# CH32X035 register map
Vendor: WCH Ltd.; File version: 1.2
Registers are 32-bit, read-write, reset 0x0 unless marked. A register's access mark holds for its fields unless they carry their own. Offsets are from the block's base; [hi:lo] are bit positions.

## I2C1 — Inter integrated circuit
Base 0x40005400
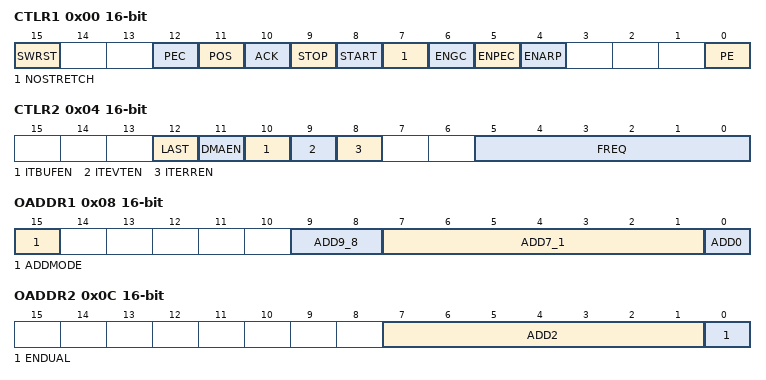
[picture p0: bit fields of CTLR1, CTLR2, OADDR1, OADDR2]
0x00 CTLR1 16-bit — Control register 1
  [15] SWRST — Software reset
  [12] PEC — Packet error checking
  [11] POS — Acknowledge/PEC Position (for data reception)
  [10] ACK — Acknowledge enable
  [9] STOP — Stop generation
  [8] START — Start generation
  [7] NOSTRETCH — Clock stretching disable (Slave mode)
  [6] ENGC — General call enable
  [5] ENPEC — PEC enable
  [4] ENARP — ARP enable
  [0] PE — Peripheral enable
0x04 CTLR2 16-bit — Control register 2
  [12] LAST — DMA last transfer
  [11] DMAEN — DMA requests enable
  [10] ITBUFEN — Buffer interrupt enable
  [9] ITEVTEN — Event interrupt enable
  [8] ITERREN — Error interrupt enable
  [5:0] FREQ — Peripheral clock frequency
0x08 OADDR1 16-bit — Own address register 1
  [15] ADDMODE — Addressing mode (slave mode)
  [9:8] ADD9_8 — Interface address
  [7:1] ADD7_1 — Interface address
  [0] ADD0 — Interface address
0x0C OADDR2 16-bit — Own address register 2
  [7:1] ADD2 — Interface address
  [0] ENDUAL — Dual addressing mode enable
0x10 DATAR 16-bit — Data register
  [7:0] DATAR — 8-bit data register
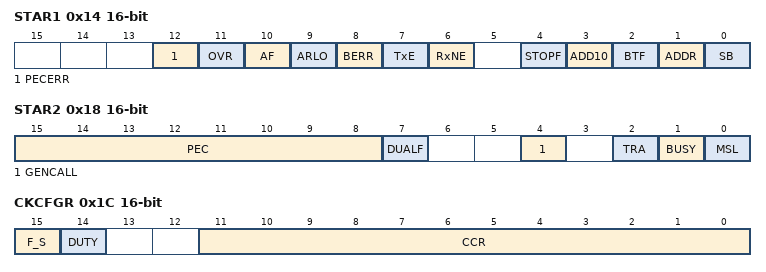
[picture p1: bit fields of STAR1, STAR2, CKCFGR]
0x14 STAR1 16-bit access per field — Status register 1
  [12] PECERR read/clear — PEC Error in reception
  [11] OVR read/clear — Overrun/Underrun
  [10] AF read/clear — Acknowledge failure
  [9] ARLO read/clear — Arbitration lost (master mode)
  [8] BERR read/clear — Bus error
  [7] TxE ro — Data register empty (transmitters)
  [6] RxNE ro — Data register not empty (receivers)
  [4] STOPF ro — Stop detection (slave mode)
  [3] ADD10 ro — 10-bit header sent (Master mode)
  [2] BTF ro — Byte transfer finished
  [1] ADDR read/clear — Address sent (master mode)/matched (slave mode)
  [0] SB ro — Start bit (Master mode)
0x18 STAR2 16-bit ro — Status register 2
  [15:8] PEC
  [7] DUALF — Dual flag (Slave mode)
  [4] GENCALL — General call address (Slave mode)
  [2] TRA — Transmitter/receiver
  [1] BUSY — Bus busy
  [0] MSL — Master/slave
0x1C CKCFGR 16-bit — Clock control register
  [15] F_S — I2C master mode selection
  [14] DUTY — Fast mode duty cycle
  [11:0] CCR — Clock control register in Fast/Standard mode (Master mode)

## SPI1 — Serial peripheral interface
Base 0x40013000
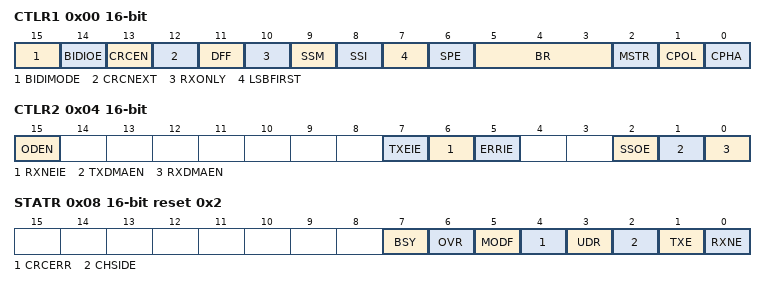
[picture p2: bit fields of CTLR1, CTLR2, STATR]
0x00 CTLR1 16-bit — control register 1
  [15] BIDIMODE — Bidirectional data mode enable
  [14] BIDIOE — Output enable in bidirectional mode
  [13] CRCEN — Hardware CRC calculation enable
  [12] CRCNEXT — CRC transfer next
  [11] DFF — Data frame format
  [10] RXONLY — Receive only
  [9] SSM — Software slave management
  [8] SSI — Internal slave select
  [7] LSBFIRST — Frame format
  [6] SPE — SPI enable
  [5:3] BR — Baud rate control
  [2] MSTR — Master selection
  [1] CPOL — Clock polarity
  [0] CPHA — Clock phase
0x04 CTLR2 16-bit — control register 2
  [15] ODEN — open drain output of SPI pin is enable
  [7] TXEIE — Tx buffer empty interrupt enable
  [6] RXNEIE — RX buffer not empty interrupt enable
  [5] ERRIE — Error interrupt enable
  [2] SSOE — SS output enable
  [1] TXDMAEN — Tx buffer DMA enable
  [0] RXDMAEN — Rx buffer DMA enable
0x08 STATR 16-bit access per field reset 0x2 — status register
  [7] BSY ro — Busy flag
  [6] OVR rw — Overrun flag
  [5] MODF ro — Mode fault
  [4] CRCERR rw — CRC error flag
  [3] UDR ro — Underrun flag
  [2] CHSIDE ro — Channel side
  [1] TXE ro — Transmit buffer empty
  [0] RXNE ro — Receive buffer not empty
0x0C DATAR 16-bit — data register
  [15:0] DR — Data register
0x10 CRCR 16-bit reset 0x7 — CRCR polynomial register
  [15:0] CRCPOLY — CRC polynomial register
0x14 RCRCR 16-bit ro — RX CRC register
  [15:0] RXCRC
0x18 TCRCR 16-bit ro — send CRC register
  [15:0] TXCRC
0x24 HSCR 16-bit wo — high speed control register
  [0] HSRXEN — High speed mode read enable
